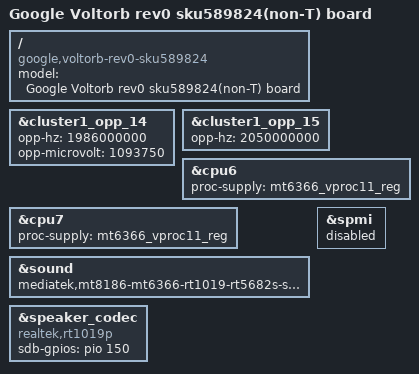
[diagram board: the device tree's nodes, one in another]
// SPDX-License-Identifier: (GPL-2.0 OR MIT)
/*
 * Copyright 2022 Google LLC
 */

/dts-v1/;
#include "mt8186-corsola-voltorb.dtsi"

/ {
	model = "Google Voltorb rev0 sku589824(non-T) board";
	compatible = "google,voltorb-rev0-sku589824", "google,voltorb",
		     "mediatek,mt8186";
};

&cluster1_opp_14 {
	opp-hz = /bits/ 64 <1986000000>;
	opp-microvolt = <1093750>;
};

&cluster1_opp_15 {
	opp-hz = /bits/ 64 <2050000000>;
};

&cpu6 {
	proc-supply = <&mt6366_vproc11_reg>;
	/delete-property/ sram-supply;
};

&cpu7 {
	proc-supply = <&mt6366_vproc11_reg>;
	/delete-property/ sram-supply;
};

&sound {
	compatible = "mediatek,mt8186-mt6366-rt1019-rt5682s-sound";
};

&speaker_codec {
	compatible = "realtek,rt1019p";
	sdb-gpios = <&pio 150 GPIO_ACTIVE_HIGH>;
	/delete-property/ sdmode-gpios;
};

&spmi {
	status = "disabled";
};
